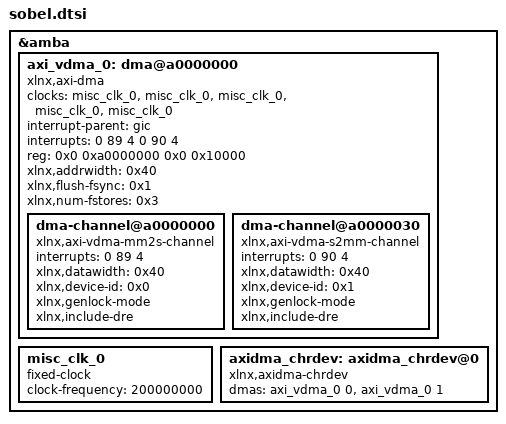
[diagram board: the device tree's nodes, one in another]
/*
 * CAUTION: This file is automatically generated by Xilinx.
 * Version:  
 * Today is: Mon Apr 26 10:38:00 2021
 */


/dts-v1/;
/plugin/;
/ {
	// fragment@0 {
	// 	target = <&fpga_full>;
	// 	overlay0: __overlay__ {
	// 		#address-cells = <2>;
	// 		#size-cells = <2>;
	// 		firmware-name = "dma_sobel.bit.bin";
	// 		resets = <&zynqmp_reset 116>;
	// 	};
	// };
	// fragment@1 {
	// 	target = <&amba>;
	// 	overlay1: __overlay__ {
	// 		afi0: afi0 {
	// 			compatible = "xlnx,afi-fpga";
	// 			config-afi = < 0 1>, <1 1>, <2 0>, <3 0>, <4 1>, <5 1>, <6 0>, <7 0>, <8 0>, <9 0>, <10 0>, <11 0>, <12 0>, <13 0>, <14 0x500>, <15 0x000>;
	// 		};
	// 		clocking0: clocking0 {
	// 			#clock-cells = <0>;
	// 			assigned-clock-rates = <100000000>;
	// 			assigned-clocks = <&zynqmp_clk 71>;
	// 			clock-output-names = "fabric_clk";
	// 			clocks = <&zynqmp_clk 71>;
	// 			compatible = "xlnx,fclk";
	// 		};
	// 	};
	// };
	fragment@2 {
		target = <&amba>;
		overlay2: __overlay__ {
			#address-cells = <2>;
			#size-cells = <2>;
            axi_vdma_0: dma@a0000000 {
				#dma-cells = <1>;
				clock-names = "s_axi_lite_aclk", "m_axi_mm2s_aclk", "m_axis_mm2s_aclk", "m_axi_s2mm_aclk", "s_axis_s2mm_aclk";
				clocks = <&misc_clk_0>, <&misc_clk_0>, <&misc_clk_0>, <&misc_clk_0>, <&misc_clk_0>;
				compatible = "xlnx,axi-dma", "xlnx,axi-vdma-6.3", "xlnx,axi-vdma-1.00.a";
				interrupt-names = "mm2s_introut", "s2mm_introut";
				interrupt-parent = <&gic>;
				interrupts = <0 89 4 0 90 4>;
				reg = <0x0 0xa0000000 0x0 0x10000>;
				xlnx,addrwidth = <0x40>;
				xlnx,flush-fsync = <0x1>;
				xlnx,num-fstores = <0x3>;
				dma-channel@a0000000 {
					compatible = "xlnx,axi-vdma-mm2s-channel";
					interrupts = <0 89 4>;
					xlnx,datawidth = <0x40>;
					xlnx,device-id = <0x0>;
					xlnx,genlock-mode ;
                    xlnx,include-dre ;
				};
				dma-channel@a0000030 {
					compatible = "xlnx,axi-vdma-s2mm-channel";
					interrupts = <0 90 4>;
					xlnx,datawidth = <0x40>;
					xlnx,device-id = <0x1>;
					xlnx,genlock-mode ;
					xlnx,include-dre ;
				};
			};
			misc_clk_0: misc_clk_0 {
				#clock-cells = <0>;
				clock-frequency = <200000000>;
				compatible = "fixed-clock";
			};
           	// sobel_accel_0: sobel_accel@a0010000 {
			// 	clock-names = "ap_clk";
			// 	clocks = <&misc_clk_0>;
			// 	compatible = "generic-uio";
			// 	interrupt-names = "interrupt";
			// 	interrupt-parent = <&gic>;
			// 	interrupts = <0 91 4>;
			// 	reg = <0x0 0xa0010000 0x0 0x10000>;
			// 	xlnx,s-axi-control-addr-width = <0x5>;
			// 	xlnx,s-axi-control-data-width = <0x20>;
			// };
		};
	};
     fragment@3 {
        target = <&amba>;
        overlay3: __overlay__ {
            axidma_chrdev: axidma_chrdev@0 {
                compatible = "xlnx,axidma-chrdev";
                dmas = <&axi_vdma_0 0 &axi_vdma_0 1>;
                dma-names = "tx_channel", "rx_channel";
            };
            // udmabuf_0: udmabuf@0 {
            //     compatible = "ikwzm,u-dma-buf";
            //     device-name = "udmabuf0";
            //     minor-number = <0>;
            //     size = <0x00100000>;
            // };
        };
	};
};
